# EZR32HG220F32R63 register map
File version: 4.0.0
CPU: CM0PLUS r0p1, little endian, no MPU, no FPU, 3 interrupt priority bits
Registers are 32-bit, read-write, reset 0x0 unless marked. A register's access mark holds for its fields unless they carry their own. Offsets are from the block's base; [hi:lo] are bit positions; {n}, {i} and the like mark numbered series; 'fields as' and 'values as' point back to an identical list.

## ADC0
Base 0x40002000
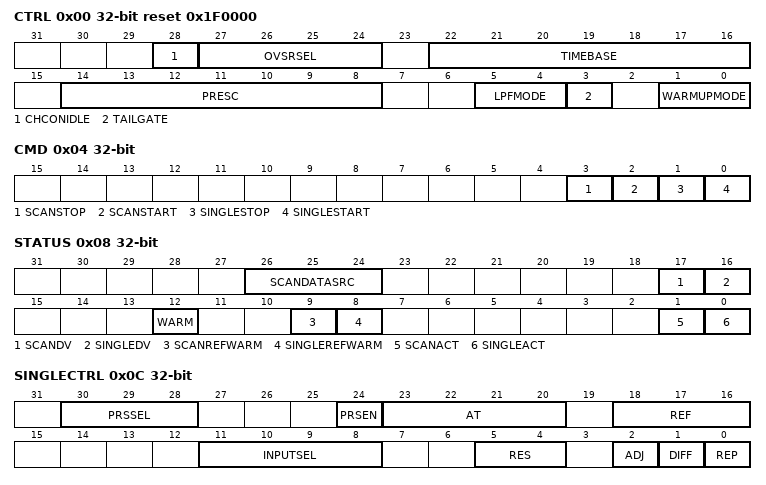
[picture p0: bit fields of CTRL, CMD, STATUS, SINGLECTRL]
0x00 CTRL reset 0x1F0000 — Control Register
  [28] CHCONIDLE — Input channel connected when ADC is IDLE
  [27:24] OVSRSEL — Oversample Rate Select
    0=X2 (2 samples for each conversion result); 1=X4 (4 samples for each conversion result); 2=X8 (8 samples for each conversion result); 3=X16 (16 samples for each conversion result); 4=X32 (32 samples for each conversion result); 5=X64 (64 samples for each conversion result); 6=X128 (128 samples for each conversion result); 7=X256 (256 samples for each conversion result); 8=X512 (512 samples for each conversion result); 9=X1024 (1024 samples for each conversion result); 10=X2048 (2048 samples for each conversion result); 11=X4096 (4096 samples for each conversion result)
  [22:16] TIMEBASE
  [14:8] PRESC — Prescaler Setting
    0=NODIVISION
  [5:4] LPFMODE — Low Pass Filter Mode
    0=BYPASS (No filter or decoupling capacitor); 1=DECAP (On chip decoupling capacitor selected); 2=RCFILT (On chip RC filter selected)
  [3] TAILGATE — Conversion Tailgating
  [1:0] WARMUPMODE
    0=NORMAL (ADC is shut down after each conversion); 1=FASTBG (Bandgap references do not need warm up, but have reduced accuracy.); 2=KEEPSCANREFWARM (Reference selected for scan mode is kept warm.); 3=KEEPADCWARM (ADC is kept warmed up and scan reference is kept warm)
0x04 CMD wo — Command Register
  [3] SCANSTOP — Scan Sequence Stop
  [2] SCANSTART — Scan Sequence Start
  [1] SINGLESTOP — Single Conversion Stop
  [0] SINGLESTART — Single Conversion Start
0x08 STATUS ro
  [26:24] SCANDATASRC — Scan Data Source
    0=CH0 (Single ended mode: SCANDATA result originates from ADCn_CH0. Differential mode: SCANDATA result originates from ADCn_CH0-ADCn_CH1); 1=CH1 (Single ended mode: SCANDATA result originates from ADCn_CH1. Differential mode: SCANDATA result originates from ADCn_CH2_ADCn_CH3); 2=CH2 (Single ended mode: SCANDATA result originates from ADCn_CH2. Differential mode: SCANDATA result originates from ADCn_CH4-ADCn_CH5); 3=CH3 (Single ended mode: SCANDATA result originates from ADCn_CH3. Differential mode: SCANDATA result originates from ADCn_CH6-ADCn_CH7); {v}=CH{v} (SCANDATA result originates from ADCn_CH{v}) (v=4..7)
  [17] SCANDV — Scan Data Valid
  [16] SINGLEDV — Single Sample Data Valid
  [12] WARM — ADC Warmed Up
  [9] SCANREFWARM — Scan Reference Warmed Up
  [8] SINGLEREFWARM — Single Reference Warmed Up
  [1] SCANACT — Scan Conversion Active
  [0] SINGLEACT — Single Conversion Active
0x0C SINGLECTRL — Single Sample Control Register
  [30:28] PRSSEL — Single Sample PRS Trigger Select
    {v}=PRSCH{v} (PRS ch {v} triggers single sample) (v=0..5)
  [24] PRSEN — Single Sample PRS Trigger Enable
  [23:20] AT — Single Sample Acquisition Time
    0=1CYCLE (1 ADC_CLK cycle acquisition time for single sample); 1=2CYCLES (2 ADC_CLK cycles acquisition time for single sample); 2=4CYCLES (4 ADC_CLK cycles acquisition time for single sample); 3=8CYCLES (8 ADC_CLK cycles acquisition time for single sample); 4=16CYCLES (16 ADC_CLK cycles acquisition time for single sample); 5=32CYCLES (32 ADC_CLK cycles acquisition time for single sample); 6=64CYCLES (64 ADC_CLK cycles acquisition time for single sample); 7=128CYCLES (128 ADC_CLK cycles acquisition time for single sample); 8=256CYCLES (256 ADC_CLK cycles acquisition time for single sample)
  [18:16] REF — Single Sample Reference Selection
    0=1V25 (Internal 1.25 V reference); 1=2V5 (Internal 2.5 V reference); 2=VDD (Buffered VDD); 3=5VDIFF (Internal differential 5 V reference); 4=EXTSINGLE (Single ended external reference from ADCn_CH6); 5=2XEXTDIFF (Differential external reference, 2x(ADCn_CH6 - ADCn_CH7)); 6=2XVDD (Unbuffered 2xVDD)
  [11:8] INPUTSEL — Single Sample Input Selection
  [5:4] RES — Single Sample Resolution Select
    0=12BIT (12-bit resolution); 1=8BIT (8-bit resolution); 2=6BIT (6-bit resolution); 3=OVS (Oversampling enabled. Oversampling rate is set in OVSRSEL)
  [2] ADJ — Single Sample Result Adjustment
  [1] DIFF — Single Sample Differential Mode
  [0] REP — Single Sample Repetitive Mode
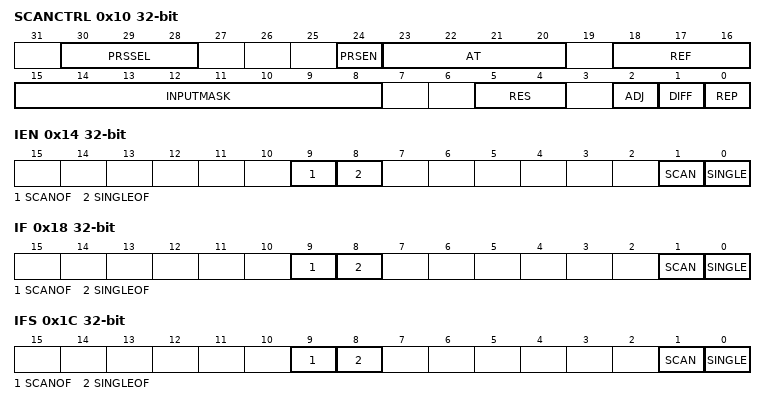
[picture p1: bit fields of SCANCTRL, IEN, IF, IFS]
0x10 SCANCTRL — Scan Control Register
  [30:28] PRSSEL — Scan Sequence PRS Trigger Select
    {v}=PRSCH{v} (PRS ch {v} triggers scan sequence) (v=0..5)
  [24] PRSEN — Scan Sequence PRS Trigger Enable
  [23:20] AT — Scan Sample Acquisition Time
    0=1CYCLE (1 ADC_CLK cycle acquisition time for scan samples); 1=2CYCLES (2 ADC_CLK cycles acquisition time for scan samples); 2=4CYCLES (4 ADC_CLK cycles acquisition time for scan samples); 3=8CYCLES (8 ADC_CLK cycles acquisition time for scan samples); 4=16CYCLES (16 ADC_CLK cycles acquisition time for scan samples); 5=32CYCLES (32 ADC_CLK cycles acquisition time for scan samples); 6=64CYCLES (64 ADC_CLK cycles acquisition time for scan samples); 7=128CYCLES (128 ADC_CLK cycles acquisition time for scan samples); 8=256CYCLES (256 ADC_CLK cycles acquisition time for scan samples)
  [18:16] REF — Scan Sequence Reference Selection
    0=1V25 (Internal 1.25 V reference); 1=2V5 (Internal 2.5 V reference); 2=VDD; 3=5VDIFF (Internal differential 5 V reference); 4=EXTSINGLE (Single ended external reference from ADCn_CH6); 5=2XEXTDIFF (Differential external reference, 2x(ADCn_CH6 - ADCn_CH7)); 6=2XVDD (Unbuffered 2xVDD)
  [15:8] INPUTMASK — Scan Sequence Input Mask
  [5:4] RES — Scan Sequence Resolution Select
    values as SINGLECTRL.RES
  [2] ADJ — Scan Sequence Result Adjustment
  [1] DIFF — Scan Sequence Differential Mode
  [0] REP — Scan Sequence Repetitive Mode
0x14 IEN — Interrupt Enable Register
  [9] SCANOF — Scan Result Overflow Interrupt Enable
  [8] SINGLEOF — Single Result Overflow Interrupt Enable
  [1] SCAN — Scan Conversion Complete Interrupt Enable
  [0] SINGLE — Single Conversion Complete Interrupt Enable
0x18 IF ro — Interrupt Flag Register
  [9] SCANOF — Scan Result Overflow Interrupt Flag
  [8] SINGLEOF — Single Result Overflow Interrupt Flag
  [1] SCAN — Scan Conversion Complete Interrupt Flag
  [0] SINGLE — Single Conversion Complete Interrupt Flag
0x1C IFS wo — Interrupt Flag Set Register
  [9] SCANOF — Scan Result Overflow Interrupt Flag Set
  [8] SINGLEOF — Single Result Overflow Interrupt Flag Set
  [1] SCAN — Scan Conversion Complete Interrupt Flag Set
  [0] SINGLE — Single Conversion Complete Interrupt Flag Set
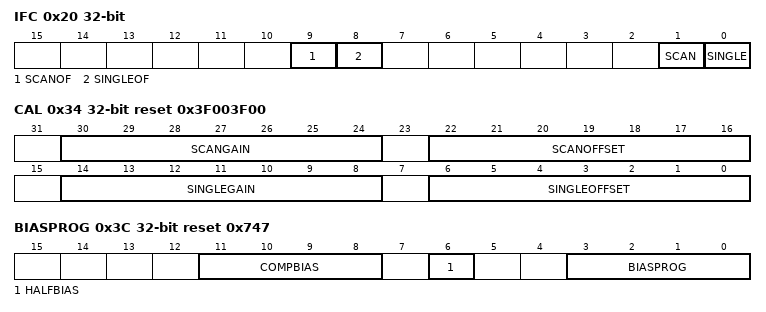
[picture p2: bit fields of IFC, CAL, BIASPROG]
0x20 IFC wo — Interrupt Flag Clear Register
  [9] SCANOF — Scan Result Overflow Interrupt Flag Clear
  [8] SINGLEOF — Single Result Overflow Interrupt Flag Clear
  [1] SCAN — Scan Conversion Complete Interrupt Flag Clear
  [0] SINGLE — Single Conversion Complete Interrupt Flag Clear
0x24 SINGLEDATA ro read-has-side-effects — Single Conversion Result Data
  [31:0] DATA
0x28 SCANDATA ro read-has-side-effects — Scan Conversion Result Data
  [31:0] DATA
0x2C SINGLEDATAP ro — Single Conversion Result Data Peek Register
  [31:0] DATAP — Single Conversion Result Data Peek
0x30 SCANDATAP ro — Scan Sequence Result Data Peek Register
  [31:0] DATAP — Scan Conversion Result Data Peek
0x34 CAL reset 0x3F003F00 — Calibration Register
  [30:24] SCANGAIN — Scan Mode Gain Calibration Value
  [22:16] SCANOFFSET — Scan Mode Offset Calibration Value
  [14:8] SINGLEGAIN — Single Mode Gain Calibration Value
  [6:0] SINGLEOFFSET — Single Mode Offset Calibration Value
0x3C BIASPROG reset 0x747 — Bias Programming Register
  [11:8] COMPBIAS — Comparator Bias Value
  [6] HALFBIAS — Half Bias Current
  [3:0] BIASPROG — Bias Programming Value

## Notices in the file
# License
Copyright 2021 Silicon Laboratories Inc. www.silabs.com
SPDX-License-Identifier: Zlib
The licensor of this software is Silicon Laboratories Inc.
This software is provided 'as-is', without any express or implied
warranty. In no event will the authors be held liable for any damages
arising from the use of this software.
Permission is granted to anyone to use this software for any purpose,
including commercial applications, and to alter it and redistribute it
freely, subject to the following restrictions:
1. The origin of this software must not be misrepresented; you must not
claim that you wrote the original software. If you use this software
in a product, an acknowledgment in the product documentation would be
appreciated but is not required.
2. Altered source versions must be plainly marked as such, and must not be
misrepresented as being the original software.
3. This notice may not be removed or altered from any source distribution.
